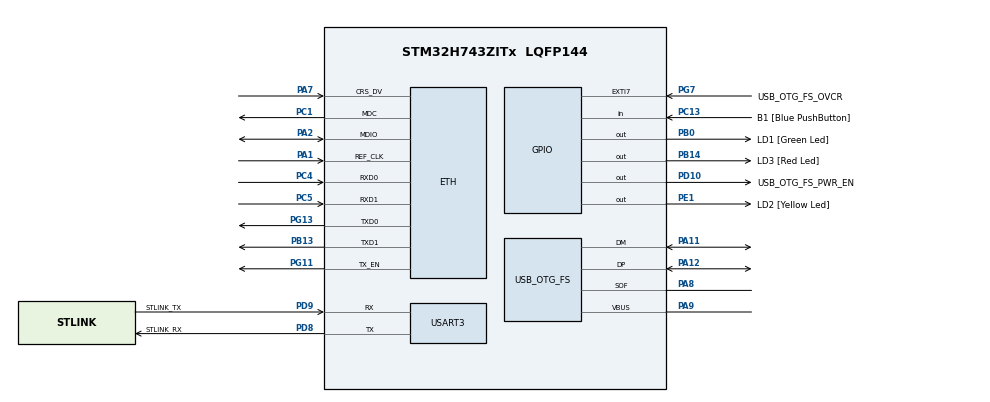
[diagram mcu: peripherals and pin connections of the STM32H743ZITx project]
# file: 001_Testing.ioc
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ETH.MediaInterface=HAL_ETH_RMII_MODE
FREERTOS.Events01=BeastmodeEvent,Dynamic,NULL
FREERTOS.Tasks01=defaultTask,24,128,StartDefaultTask,Default,NULL,Dynamic,NULL,NULL
FREERTOS.configUSE_NEWLIB_REENTRANT=1
Mcu.Family=STM32H7
Mcu.Name=STM32H743ZITx
Mcu.Package=LQFP144
NVIC.PriorityGroup=NVIC_PRIORITYGROUP_4
NVIC.TIM1_UP_IRQn=true\:15\:0\:false\:false\:true\:false\:false\:true\:true
NVIC.TimeBase=TIM1_UP_IRQn
NVIC.TimeBaseIP=TIM1
PA1.Mode=RMII
PA1.Signal=ETH_REF_CLK
PA11.Mode=Device_Only
PA11.Signal=USB_OTG_FS_DM
PA12.Mode=Device_Only
PA12.Signal=USB_OTG_FS_DP
PA2.Mode=RMII
PA2.Signal=ETH_MDIO
PA7.Mode=RMII
PA7.Signal=ETH_CRS_DV
PA8.Mode=Activate_SOF_FS
PA8.Signal=USB_OTG_FS_SOF
PA9.Mode=Activate_VBUS
PA9.Signal=USB_OTG_FS_VBUS
PB0.GPIO_Label=LD1 [Green Led]
PB0.Signal=GPIO_Output
PB13.Mode=RMII
PB13.Signal=ETH_TXD1
PB14.GPIO_Label=LD3 [Red Led]
PB14.Signal=GPIO_Output
PC1.Mode=RMII
PC1.Signal=ETH_MDC
PC13.GPIO_Label=B1 [Blue PushButton]
PC13.Signal=GPIO_Input
PC14-OSC32_IN\ (OSC32_IN).Mode=LSE-External-Oscillator
PC14-OSC32_IN\ (OSC32_IN).Signal=RCC_OSC32_IN
PC15-OSC32_OUT\ (OSC32_OUT).Mode=LSE-External-Oscillator
PC15-OSC32_OUT\ (OSC32_OUT).Signal=RCC_OSC32_OUT
PC4.Mode=RMII
PC4.Signal=ETH_RXD0
PC5.Mode=RMII
PC5.Signal=ETH_RXD1
PD10.GPIO_Label=USB_OTG_FS_PWR_EN
PD10.Signal=GPIO_Output
PD8.GPIO_Label=STLINK_RX
PD8.Mode=Asynchronous
PD8.Signal=USART3_TX
PD9.GPIO_Label=STLINK_TX
PD9.Mode=Asynchronous
PD9.Signal=USART3_RX
PE1.GPIO_Label=LD2 [Yellow Led]
PE1.Signal=GPIO_Output
PG11.Mode=RMII
PG11.Signal=ETH_TX_EN
PG13.Mode=RMII
PG13.Signal=ETH_TXD0
PG7.GPIO_Label=USB_OTG_FS_OVCR
PG7.Signal=GPXTI7
PH0-OSC_IN\ (PH0).Mode=HSE-External-Clock-Source
PH0-OSC_IN\ (PH0).Signal=RCC_OSC_IN
PH1-OSC_OUT\ (PH1).Signal=RCC_OSC_OUT
ProjectManager.HeapSize=0x200
ProjectManager.StackSize=0x400
ProjectManager.TargetToolchain=STM32CubeIDE
RCC.ADCFreq_Value=16125000
RCC.APB1Freq_Value=120000000
RCC.APB2Freq_Value=120000000
RCC.APB3Freq_Value=120000000
RCC.APB4Freq_Value=120000000
RCC.CortexFreq_Value=480000000
RCC.D1PPRE=RCC_APB3_DIV2
RCC.D2PPRE1=RCC_APB1_DIV2
RCC.D2PPRE2=RCC_APB2_DIV2
RCC.D3PPRE=RCC_APB4_DIV2
RCC.DIVM1=1
RCC.DIVN1=120
RCC.DIVQ1=15
RCC.HCLKFreq_Value=240000000
RCC.HPRE=RCC_HCLK_DIV2
RCC.HSE_VALUE=8000000
RCC.PLL2FRACN=0
RCC.PLL3FRACN=0
RCC.PLLFRACN=0
RCC.PWR_Regulator_Voltage_Scale=PWR_REGULATOR_VOLTAGE_SCALE0
RCC.SYSCLKFreq_VALUE=480000000
RCC.SYSCLKSource=RCC_SYSCLKSOURCE_PLLCLK
RCC.USBFreq_Value=64000000
USART3.VirtualMode-Asynchronous=VM_ASYNC
USB_OTG_FS.VirtualMode=Device_Only
VP_FREERTOS_VS_CMSIS_V2.Mode=CMSIS_V2
VP_SYS_VS_tim1.Mode=TIM1
board=NUCLEO-H743ZI2

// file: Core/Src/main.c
/* USER CODE BEGIN Header */
/**
  ******************************************************************************
  * @file           : main.c
  * @brief          : Main program body
  ******************************************************************************
  * @attention
  *
  * Copyright (c) 2023 STMicroelectronics.
  * All rights reserved.
  *
  * This software is licensed under terms that can be found in the LICENSE file
  * in the root directory of this software component.
  * If no LICENSE file comes with this software, it is provided AS-IS.
  *
  ******************************************************************************
  */
/* USER CODE END Header */
#include "main.h"
#include "cmsis_os.h"
#include "eth.h"
#include "usart.h"
#include "usb_otg.h"
#include "gpio.h"

void SystemClock_Config(void);
void MX_FREERTOS_Init(void);

/* USER CODE BEGIN 0 */
asm(".global _printf_float");
/* USER CODE END 0 */

int main(void)
{

  /* MCU Configuration--------------------------------------------------------*/

  /* Reset of all peripherals, Initializes the Flash interface and the Systick. */
  HAL_Init();

  /* Configure the system clock */
  SystemClock_Config();

  /* Initialize all configured peripherals */
  MX_GPIO_Init();
  MX_ETH_Init();
  MX_USART3_UART_Init();
  MX_USB_OTG_FS_PCD_Init();

  /* Init scheduler */
  osKernelInitialize();

  /* Call init function for freertos objects (in freertos.c) */
  MX_FREERTOS_Init();

  /* Start scheduler */
  osKernelStart();

  /* We should never get here as control is now taken by the scheduler */
  /* Infinite loop */
  while (1)
  {

  }
}

void SystemClock_Config(void)
{
  RCC_OscInitTypeDef RCC_OscInitStruct = {0};
  RCC_ClkInitTypeDef RCC_ClkInitStruct = {0};

  /** Supply configuration update enable
  */
  HAL_PWREx_ConfigSupply(PWR_LDO_SUPPLY);

  /** Configure the main internal regulator output voltage
  */
  __HAL_PWR_VOLTAGESCALING_CONFIG(PWR_REGULATOR_VOLTAGE_SCALE1);

  while(!__HAL_PWR_GET_FLAG(PWR_FLAG_VOSRDY)) {}

  __HAL_RCC_SYSCFG_CLK_ENABLE();
  __HAL_PWR_VOLTAGESCALING_CONFIG(PWR_REGULATOR_VOLTAGE_SCALE0);

  while(!__HAL_PWR_GET_FLAG(PWR_FLAG_VOSRDY)) {}

  /** Initializes the RCC Oscillators according to the specified parameters
  * in the RCC_OscInitTypeDef structure.
  */
  RCC_OscInitStruct.OscillatorType = RCC_OSCILLATORTYPE_HSE;
  RCC_OscInitStruct.HSEState = RCC_HSE_BYPASS;
  RCC_OscInitStruct.PLL.PLLState = RCC_PLL_ON;
  RCC_OscInitStruct.PLL.PLLSource = RCC_PLLSOURCE_HSE;
  RCC_OscInitStruct.PLL.PLLM = 1;
  RCC_OscInitStruct.PLL.PLLN = 120;
  RCC_OscInitStruct.PLL.PLLP = 2;
  RCC_OscInitStruct.PLL.PLLQ = 15;
  RCC_OscInitStruct.PLL.PLLR = 2;
  RCC_OscInitStruct.PLL.PLLRGE = RCC_PLL1VCIRANGE_3;
  RCC_OscInitStruct.PLL.PLLVCOSEL = RCC_PLL1VCOWIDE;
  RCC_OscInitStruct.PLL.PLLFRACN = 0;
  if (HAL_RCC_OscConfig(&RCC_OscInitStruct) != HAL_OK)
  {
    Error_Handler();
  }

  /** Initializes the CPU, AHB and APB buses clocks
  */
  RCC_ClkInitStruct.ClockType = RCC_CLOCKTYPE_HCLK|RCC_CLOCKTYPE_SYSCLK
                              |RCC_CLOCKTYPE_PCLK1|RCC_CLOCKTYPE_PCLK2
                              |RCC_CLOCKTYPE_D3PCLK1|RCC_CLOCKTYPE_D1PCLK1;
  RCC_ClkInitStruct.SYSCLKSource = RCC_SYSCLKSOURCE_PLLCLK;
  RCC_ClkInitStruct.SYSCLKDivider = RCC_SYSCLK_DIV1;
  RCC_ClkInitStruct.AHBCLKDivider = RCC_HCLK_DIV2;
  RCC_ClkInitStruct.APB3CLKDivider = RCC_APB3_DIV2;
  RCC_ClkInitStruct.APB1CLKDivider = RCC_APB1_DIV2;
  RCC_ClkInitStruct.APB2CLKDivider = RCC_APB2_DIV2;
  RCC_ClkInitStruct.APB4CLKDivider = RCC_APB4_DIV2;

  if (HAL_RCC_ClockConfig(&RCC_ClkInitStruct, FLASH_LATENCY_4) != HAL_OK)
  {
    Error_Handler();
  }
}

void HAL_TIM_PeriodElapsedCallback(TIM_HandleTypeDef *htim)
{
  if (htim->Instance == TIM1) {
    HAL_IncTick();
  }
}

void Error_Handler(void)
{
  __disable_irq();
  while (1)
  {
  }
}

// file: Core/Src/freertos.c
/* USER CODE BEGIN Header */
/**
  ******************************************************************************
  * File Name          : freertos.c
  * Description        : Code for freertos applications
  ******************************************************************************
  * @attention
  *
  * Copyright (c) 2023 STMicroelectronics.
  * All rights reserved.
  *
  * This software is licensed under terms that can be found in the LICENSE file
  * in the root directory of this software component.
  * If no LICENSE file comes with this software, it is provided AS-IS.
  *
  ******************************************************************************
  */
/* USER CODE END Header */

#include "FreeRTOS.h"
#include "task.h"
#include "main.h"
#include "cmsis_os.h"

/* USER CODE BEGIN Variables */

extern UART_HandleTypeDef huart3;

/* USER CODE END Variables */
/* Definitions for defaultTask */
osThreadId_t defaultTaskHandle;
const osThreadAttr_t defaultTask_attributes = {
  .name = "defaultTask",
  .stack_size = 128 * 4,
  .priority = (osPriority_t) osPriorityNormal,
};
/* Definitions for BeastmodeEvent */
osEventFlagsId_t BeastmodeEventHandle;
const osEventFlagsAttr_t BeastmodeEvent_attributes = {
  .name = "BeastmodeEvent"
};

void StartDefaultTask(void *argument);

void MX_FREERTOS_Init(void); /* (MISRA C 2004 rule 8.1) */

void MX_FREERTOS_Init(void) {

  /* Create the thread(s) */
  /* creation of defaultTask */
  defaultTaskHandle = osThreadNew(StartDefaultTask, NULL, &defaultTask_attributes);

  /* Create the event(s) */
  /* creation of BeastmodeEvent */
  BeastmodeEventHandle = osEventFlagsNew(&BeastmodeEvent_attributes);

}

void StartDefaultTask(void *argument)
{
    /* USER CODE BEGIN StartDefaultTask */
    /* Infinite loop */
	char msg[ 50 ];
	float beast = 655.22;
	sprintf( msg, "Example Floating Point: %f\r\n", beast);
    for(;;)
    {
		HAL_UART_Transmit( &huart3, ( uint8_t * )msg, strlen( msg ), 1000 );
        osDelay( 500 );
    }
    /* USER CODE END StartDefaultTask */
}
